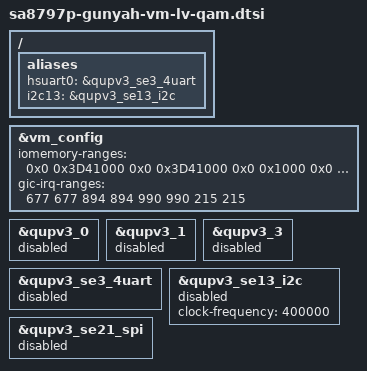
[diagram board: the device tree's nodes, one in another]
// SPDX-License-Identifier: BSD-3-Clause
/*
 * Copyright (c) Qualcomm Technologies, Inc. and/or its subsidiaries.
 */

#include "sa8797p-gunyah-vm-lv.dtsi"
#include "sa8797p-gunyah-vm-qupv3.dtsi"

/ {
	aliases {
		hsuart0 = &qupv3_se3_4uart;
		i2c13 = &qupv3_se13_i2c;
	};
};

&vm_config {
	/* Pass through regions */
	iomemory-ranges = <
		/* GPU region */
		0x0 0x3D41000 0x0 0x3D41000 0x0 0x1000 0x0
		0x0 0x9841000 0x0 0x9841000 0x0 0x1000 0x0
		/* MPROC NS2 IPCC region */
		0x0 0x9009000 0x0 0x9009000 0x0 0x1000 0x0
		/* VCODEC CS1 region */
		0x0 0xAAA2000 0x0 0xAAA2000 0x0 0x1000 0x0
	>;

	/* Pass through IRQs */
	gic-irq-ranges = <
		/* GPU GIC IRQ */
		677 677
		894 894
		/* MPROC NS2 IPCC GIC IRQ */
		990 990
		/* VCODEC CS1 */
		215 215
	>;
};

&qupv3_0 {
	status = "disabled";
};

&qupv3_1 {
	status = "disabled";
};

&qupv3_3 {
	status = "disabled";
};

&qupv3_se3_4uart {
	status = "disabled";
};

&qupv3_se13_i2c {
	clock-frequency = <400000>;
	status = "disabled";
};

&qupv3_se21_spi {
	status = "disabled";
};
